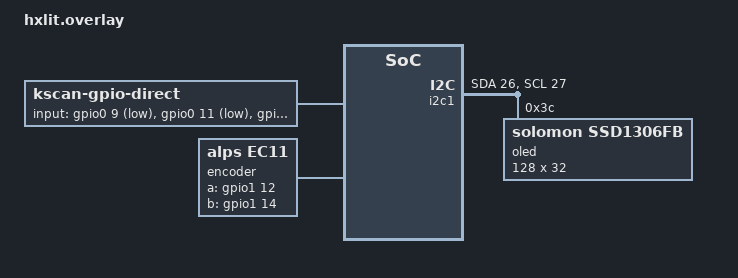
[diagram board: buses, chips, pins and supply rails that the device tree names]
/ {
    chosen {
        zephyr,display = &oled;
        zmk,kscan = &kscan0;
    };

    kscan0: kscan {
        compatible = "zmk,kscan-gpio-direct";
        label = "KSCAN";
        input-gpios =
            <&gpio0 9  (GPIO_ACTIVE_LOW | GPIO_PULL_UP)>,
            <&gpio0 11 (GPIO_ACTIVE_LOW | GPIO_PULL_UP)>,
            <&gpio0 10 (GPIO_ACTIVE_LOW | GPIO_PULL_UP)>,
            <&gpio1 13 (GPIO_ACTIVE_LOW | GPIO_PULL_UP)>;
    };

    encoder: encoder {
        compatible = "alps,ec11";
        a-gpios = <&gpio1 12 (GPIO_ACTIVE_HIGH | GPIO_PULL_UP)>;
        b-gpios = <&gpio1 14 (GPIO_ACTIVE_HIGH | GPIO_PULL_UP)>;
        steps = <24>;
        status = "okay";
    };

    sensors: sensors {
        compatible = "zmk,keymap-sensors";
        sensors = <&encoder>;
        triggers-per-rotation = <12>;
    };
};

&i2c1 {
    status = "okay";
    sda-pin = <26>;
    scl-pin = <27>;

    oled: ssd1306@3c {
        compatible = "solomon,ssd1306fb";
        reg = <0x3c>;
        width = <128>;
        height = <32>;
        segment-offset = <0>;
        page-offset = <0>;
        display-offset = <0>;
        multiplex-ratio = <31>;
        com-invdir;
        segment-remap;
        com-sequential;
        prechargep = <0x22>;
    };
};
